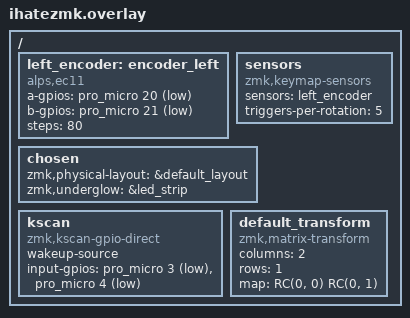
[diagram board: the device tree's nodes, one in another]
// This file was generated from a template. Edit it to match your keyboard.
// See https://zmk.dev/docs/development/hardware-integration/new-shield for more
// instructions.

#include <dt-bindings/zmk/matrix_transform.h>

#include "ihatezmk-layouts.dtsi"

/ {
    left_encoder: encoder_left {
        compatible = "alps,ec11";
        a-gpios = <&pro_micro 20 (GPIO_ACTIVE_LOW | GPIO_PULL_UP)>;
        b-gpios = <&pro_micro 21 (GPIO_ACTIVE_LOW | GPIO_PULL_UP)>;
        steps = <80>;
        status = "okay";
    };

       sensors {
        compatible = "zmk,keymap-sensors";
        sensors = <&left_encoder>;
        triggers-per-rotation = <5>;
    };

    chosen {
        zmk,physical-layout = &default_layout;
        zmk,underglow = &led_strip;
    };

    kscan: kscan {
        // If the hardware does not use a switch matrix, change this to the
        // appropriate driver and update the properties below to match.
        // See https://zmk.dev/docs/config/kscan for supported key scan drivers.
        compatible = "zmk,kscan-gpio-direct";
        wakeup-source;

        // Replace these comments with the GPIO pins in the matrix.
        // See https://zmk.dev/docs/development/hardware-integration/new-shield#shield-overlays
        input-gpios
            = <&pro_micro 3 (GPIO_ACTIVE_LOW | GPIO_PULL_UP)>
            , <&pro_micro 4 (GPIO_ACTIVE_LOW | GPIO_PULL_UP)>
            ;
    };

    default_transform: default_transform {
        // See https://zmk.dev/docs/development/hardware-integration/new-shield#matrix-transform
        // for how to configure this
        compatible = "zmk,matrix-transform";
        columns = <2>;
        rows = <1>;

        map = <
            RC(0, 0) RC(0, 1)
        >;
    };
};
